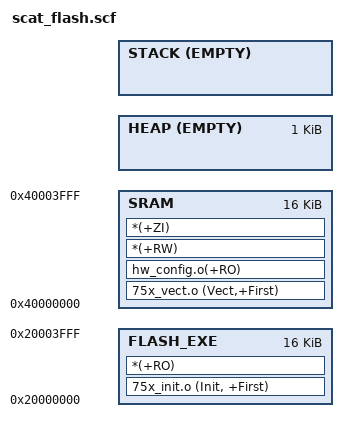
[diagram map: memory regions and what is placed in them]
;******************** (C) COPYRIGHT 2006 STMicroelectronics ********************
;* File Name          : scat_flash.scf
;* Author             : MCD Application Team
;* Date First Issued  : 10/01/2006 : V1.0
;* Description        : This file provides an example of a scatterloading
;*                      descriptor file that defines one load region in the
;*                      Embedded Flash(Bank 1) and four execution regions.
;*******************************************************************************
;* History:
;* 10/01/2006 : V1.0
;*******************************************************************************
; THE PRESENT SOFTWARE WHICH IS FOR GUIDANCE ONLY AIMS AT PROVIDING CUSTOMERS
; WITH CODING INFORMATION REGARDING THEIR PRODUCTS IN ORDER FOR THEM TO SAVE TIME.
; AS A RESULT, STMICROELECTRONICS SHALL NOT BE HELD LIABLE FOR ANY DIRECT,
; INDIRECT OR CONSEQUENTIAL DAMAGES WITH RESPECT TO ANY CLAIMS ARISING FROM THE
; CONTENT OF SUCH SOFTWARE AND/OR THE USE MADE BY CUSTOMERS OF THE CODING
; INFORMATION CONTAINED HEREIN IN CONNECTION WITH THEIR PRODUCTS.
;*******************************************************************************


FLASH_LOAD 0x20000000  0x4000  ;  Flash bank0 sector 0 & 1
{

    FLASH_EXE 0x20000000  0x4000 ; 
    {
         75x_init.o (Init, +First)
         *(+RO)
         ;*(InRoot$$Sections)        ; this section must be in a root region
    
    }

    ; Embedded RAM  (16Kbytes)

    SRAM 0x40000000  0x4000
    {
         75x_vect.o (Vect,+First)
         hw_config.o(+RO) ; contains flash routines
         *(+RW)
         *(+ZI)
    }

    ; Heap will grow just above ZI region :
    ; This Symbol is exported to "75x_init.s" file

    HEAP +0 EMPTY 0x400
    {
    }

    ; Stack Base address exported to "75x_init.s" file ( Top of SRAM )

    STACK 0x40004000 EMPTY -0x0
    {
    }
}

;******************* (C) COPYRIGHT 2006 STMicroelectronics *****END OF FILE*****
